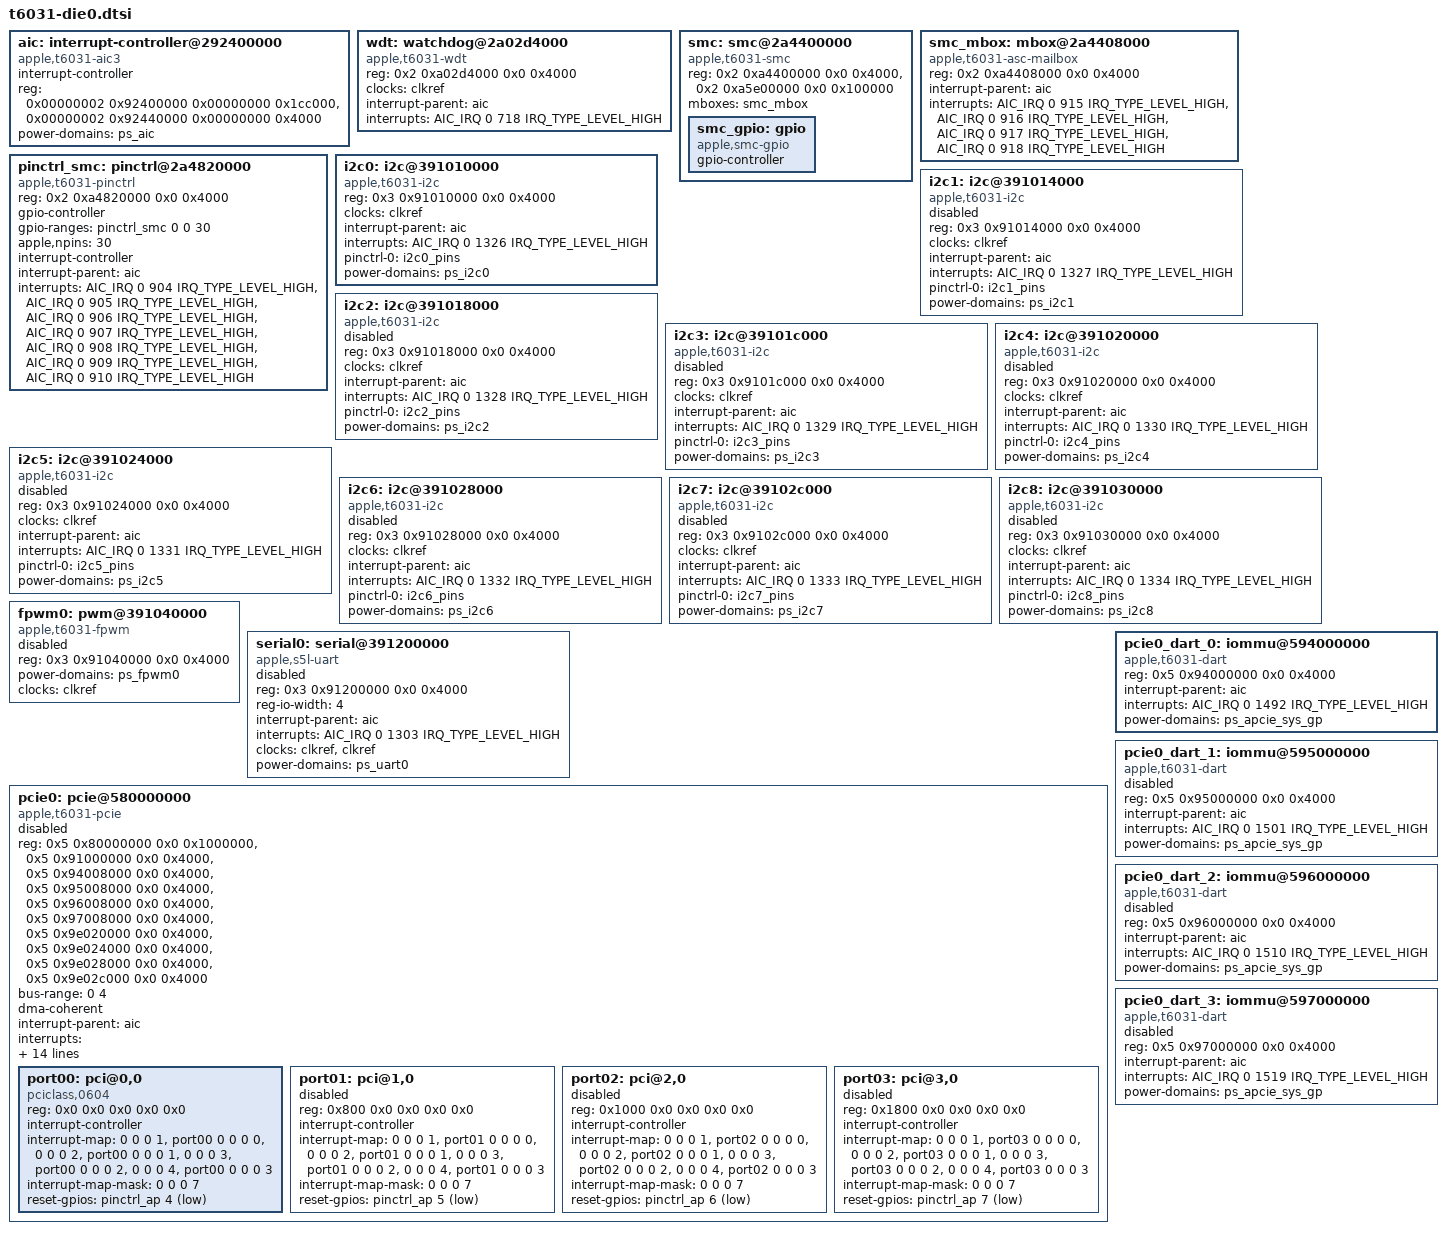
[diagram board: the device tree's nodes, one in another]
// SPDX-License-Identifier: GPL-2.0+ OR MIT
/*
 * Devices used on die 0 on the Apple T6032 "M3 Ultra" SoC and present on
 * Apple T6030 ("M3 Pro") and T6031 / T6034 ("M3 Max").
 *
 * Copyright The Asahi Linux Contributors
 */

#include <dt-bindings/gpio/gpio.h>

	aic: interrupt-controller@292400000 {
		compatible = "apple,t6031-aic3", "apple,t8122-aic3";
		#interrupt-cells = <4>;
		interrupt-controller;

		reg = <0x00000002 0x92400000 0x00000000 0x1cc000>,
		      <0x00000002 0x92440000 0x00000000 0x4000>;
		reg-names = "core", "event";
		power-domains = <&ps_aic>;
	};

	wdt: watchdog@2a02d4000 {
		compatible = "apple,t6031-wdt", "apple,t8103-wdt";
		reg = <0x2 0xa02d4000 0x0 0x4000>;
		clocks = <&clkref>;
		interrupt-parent = <&aic>;
		interrupts = <AIC_IRQ 0 718 IRQ_TYPE_LEVEL_HIGH>;
	};

	smc: smc@2a4400000 {
		compatible = "apple,t6031-smc", "apple,smc";
		reg =
			<0x2 0xa4400000 0x0 0x4000>,
			<0x2 0xa5e00000 0x0 0x100000>;
		reg-names = "smc", "sram";
		mboxes = <&smc_mbox>;

		smc_gpio: gpio {
			compatible = "apple,smc-gpio";
			#gpio-cells = <2>;
			gpio-controller;
		};
	};

	smc_mbox: mbox@2a4408000 {
		compatible = "apple,t6031-asc-mailbox", "apple,asc-mailbox-v4";
		reg = <0x2 0xa4408000 0x0 0x4000>;
		interrupt-parent = <&aic>;
		interrupts =
			<AIC_IRQ 0 915 IRQ_TYPE_LEVEL_HIGH>,
			<AIC_IRQ 0 916 IRQ_TYPE_LEVEL_HIGH>,
			<AIC_IRQ 0 917 IRQ_TYPE_LEVEL_HIGH>,
			<AIC_IRQ 0 918 IRQ_TYPE_LEVEL_HIGH>;
		interrupt-names =
			"send-empty",
			"send-not-empty",
			"recv-empty",
			"recv-not-empty";
		#mbox-cells = <0>;
	};

	pinctrl_smc: pinctrl@2a4820000 {
		compatible = "apple,t6031-pinctrl", "apple,t8103-pinctrl";
		reg = <0x2 0xa4820000 0x0 0x4000>;

		gpio-controller;
		#gpio-cells = <2>;
		gpio-ranges = <&pinctrl_smc 0 0 30>;
		apple,npins = <30>;

		interrupt-controller;
		#interrupt-cells = <2>;
		interrupt-parent = <&aic>;
		interrupts = <AIC_IRQ 0 904 IRQ_TYPE_LEVEL_HIGH>,
				<AIC_IRQ 0 905 IRQ_TYPE_LEVEL_HIGH>,
				<AIC_IRQ 0 906 IRQ_TYPE_LEVEL_HIGH>,
				<AIC_IRQ 0 907 IRQ_TYPE_LEVEL_HIGH>,
				<AIC_IRQ 0 908 IRQ_TYPE_LEVEL_HIGH>,
				<AIC_IRQ 0 909 IRQ_TYPE_LEVEL_HIGH>,
				<AIC_IRQ 0 910 IRQ_TYPE_LEVEL_HIGH>;
	};

	i2c0: i2c@391010000 {
		compatible = "apple,t6031-i2c", "apple,t8103-i2c";
		reg = <0x3 0x91010000 0x0 0x4000>;
		clocks = <&clkref>;
		interrupt-parent = <&aic>;
		interrupts = <AIC_IRQ 0 1326 IRQ_TYPE_LEVEL_HIGH>;
		pinctrl-0 = <&i2c0_pins>;
		pinctrl-names = "default";
		power-domains = <&ps_i2c0>;
		#address-cells = <0x1>;
		#size-cells = <0x0>;
	};

	i2c1: i2c@391014000 {
		compatible = "apple,t6031-i2c", "apple,t8103-i2c";
		reg = <0x3 0x91014000 0x0 0x4000>;
		clocks = <&clkref>;
		interrupt-parent = <&aic>;
		interrupts = <AIC_IRQ 0 1327 IRQ_TYPE_LEVEL_HIGH>;
		pinctrl-0 = <&i2c1_pins>;
		pinctrl-names = "default";
		power-domains = <&ps_i2c1>;
		#address-cells = <0x1>;
		#size-cells = <0x0>;
		status = "disabled";
	};

	i2c2: i2c@391018000 {
		compatible = "apple,t6031-i2c", "apple,t8103-i2c";
		reg = <0x3 0x91018000 0x0 0x4000>;
		clocks = <&clkref>;
		interrupt-parent = <&aic>;
		interrupts = <AIC_IRQ 0 1328 IRQ_TYPE_LEVEL_HIGH>;
		pinctrl-0 = <&i2c2_pins>;
		pinctrl-names = "default";
		power-domains = <&ps_i2c2>;
		#address-cells = <0x1>;
		#size-cells = <0x0>;
		status = "disabled";
	};

	i2c3: i2c@39101c000 {
		compatible = "apple,t6031-i2c", "apple,t8103-i2c";
		reg = <0x3 0x9101c000 0x0 0x4000>;
		clocks = <&clkref>;
		interrupt-parent = <&aic>;
		interrupts = <AIC_IRQ 0 1329 IRQ_TYPE_LEVEL_HIGH>;
		pinctrl-0 = <&i2c3_pins>;
		pinctrl-names = "default";
		power-domains = <&ps_i2c3>;
		#address-cells = <0x1>;
		#size-cells = <0x0>;
		status = "disabled";
	};

	i2c4: i2c@391020000 {
		compatible = "apple,t6031-i2c", "apple,t8103-i2c";
		reg = <0x3 0x91020000 0x0 0x4000>;
		clocks = <&clkref>;
		interrupt-parent = <&aic>;
		interrupts = <AIC_IRQ 0 1330 IRQ_TYPE_LEVEL_HIGH>;
		pinctrl-0 = <&i2c4_pins>;
		pinctrl-names = "default";
		power-domains = <&ps_i2c4>;
		#address-cells = <0x1>;
		#size-cells = <0x0>;
		status = "disabled";
	};

	i2c5: i2c@391024000 {
		compatible = "apple,t6031-i2c", "apple,t8103-i2c";
		reg = <0x3 0x91024000 0x0 0x4000>;
		clocks = <&clkref>;
		interrupt-parent = <&aic>;
		interrupts = <AIC_IRQ 0 1331 IRQ_TYPE_LEVEL_HIGH>;
		pinctrl-0 = <&i2c5_pins>;
		pinctrl-names = "default";
		power-domains = <&ps_i2c5>;
		#address-cells = <0x1>;
		#size-cells = <0x0>;
		status = "disabled";
	};

	i2c6: i2c@391028000 {
		compatible = "apple,t6031-i2c", "apple,t8103-i2c";
		reg = <0x3 0x91028000 0x0 0x4000>;
		clocks = <&clkref>;
		interrupt-parent = <&aic>;
		interrupts = <AIC_IRQ 0 1332 IRQ_TYPE_LEVEL_HIGH>;
		pinctrl-0 = <&i2c6_pins>;
		pinctrl-names = "default";
		power-domains = <&ps_i2c6>;
		#address-cells = <0x1>;
		#size-cells = <0x0>;
		status = "disabled";
	};

	i2c7: i2c@39102c000 {
		compatible = "apple,t6031-i2c", "apple,t8103-i2c";
		reg = <0x3 0x9102c000 0x0 0x4000>;
		clocks = <&clkref>;
		interrupt-parent = <&aic>;
		interrupts = <AIC_IRQ 0 1333 IRQ_TYPE_LEVEL_HIGH>;
		pinctrl-0 = <&i2c7_pins>;
		pinctrl-names = "default";
		power-domains = <&ps_i2c7>;
		#address-cells = <0x1>;
		#size-cells = <0x0>;
		status = "disabled";
	};

	i2c8: i2c@391030000 {
		compatible = "apple,t6031-i2c", "apple,t8103-i2c";
		reg = <0x3 0x91030000 0x0 0x4000>;
		clocks = <&clkref>;
		interrupt-parent = <&aic>;
		interrupts = <AIC_IRQ 0 1334 IRQ_TYPE_LEVEL_HIGH>;
		pinctrl-0 = <&i2c8_pins>;
		pinctrl-names = "default";
		power-domains = <&ps_i2c8>;
		#address-cells = <0x1>;
		#size-cells = <0x0>;
		status = "disabled";
	};

	fpwm0: pwm@391040000 {
		compatible = "apple,t6031-fpwm", "apple,s5l-fpwm";
		reg = <0x3 0x91040000 0x0 0x4000>;
		power-domains = <&ps_fpwm0>;
		clocks = <&clkref>;
		#pwm-cells = <2>;
		status = "disabled";
	};

	serial0: serial@391200000 {
		compatible = "apple,s5l-uart";
		reg = <0x3 0x91200000 0x0 0x4000>;
		reg-io-width = <4>;
		interrupt-parent = <&aic>;
		interrupts = <AIC_IRQ 0 1303 IRQ_TYPE_LEVEL_HIGH>;
		/*
		 * TODO: figure out the clocking properly, there may
		 * be a third selectable clock.
		 */
		clocks = <&clkref>, <&clkref>;
		clock-names = "uart", "clk_uart_baud0";
		power-domains = <&ps_uart0>;
		status = "disabled";
	};

	pcie0: pcie@580000000 {
		device_type = "pci";
		compatible = "apple,t6031-pcie", "apple,t6020-pcie";
		reg =
			<0x5 0x80000000 0x0 0x1000000>,
			<0x5 0x91000000 0x0 0x4000>,
			<0x5 0x94008000 0x0 0x4000>,
			<0x5 0x95008000 0x0 0x4000>,
			<0x5 0x96008000 0x0 0x4000>,
			<0x5 0x97008000 0x0 0x4000>,
			<0x5 0x9e020000 0x0 0x4000>,
			<0x5 0x9e024000 0x0 0x4000>,
			<0x5 0x9e028000 0x0 0x4000>,
			<0x5 0x9e02c000 0x0 0x4000>;
		reg-names =
			"config",
			"rc",
			"port0",
			"port1",
			"port2",
			"port3",
			"phy0",
			"phy1",
			"phy2",
			"phy3";
		ranges =
			<0x43000000 0x5 0xa0000000 0x5 0xa0000000 0x0
			0x20000000>,
			<0x02000000 0x0 0xc0000000 0x5 0xc0000000 0x0
			0x40000000>;
		#address-cells = <3>;
		bus-range = <0 4>;
		dma-coherent;
		interrupt-parent = <&aic>;
		interrupts =
			<AIC_IRQ 0 1491 IRQ_TYPE_LEVEL_HIGH>,
			<AIC_IRQ 0 1500 IRQ_TYPE_LEVEL_HIGH>,
			<AIC_IRQ 0 1509 IRQ_TYPE_LEVEL_HIGH>,
			<AIC_IRQ 0 1518 IRQ_TYPE_LEVEL_HIGH>;
		iommu-map =
			<0x100 &pcie0_dart_0 1 1>,
			<0x200 &pcie0_dart_1 1 1>,
			<0x300 &pcie0_dart_2 1 1>,
			<0x400 &pcie0_dart_3 1 1>;
		iommu-map-mask = <0xff00>;
		msi-controller;
		msi-parent = <&pcie0>;
		msi-ranges = <&aic AIC_IRQ 0 1854 IRQ_TYPE_EDGE_RISING 32>;
		pinctrl-0 = <&pcie_pins>;
		pinctrl-names = "default";
		power-domains = <&ps_apcie_sys_gp>;
		#size-cells = <2>;

		status = "disabled";

		port00: pci@0,0 {
			device_type = "pci";
			compatible = "pciclass,0604";
			reg = <0x0 0x0 0x0 0x0 0x0>;
			ranges;
			#address-cells = <3>;
			#interrupt-cells = <1>;
			interrupt-controller;
			interrupt-map =
				<0 0 0 1 &port00 0 0 0 0>,
				<0 0 0 2 &port00 0 0 0 1>,
				<0 0 0 3 &port00 0 0 0 2>,
				<0 0 0 4 &port00 0 0 0 3>;
			interrupt-map-mask = <0 0 0 7>;
			reset-gpios = <&pinctrl_ap 4 GPIO_ACTIVE_LOW>;
			#size-cells = <2>;
		};

		port01: pci@1,0 {
			device_type = "pci";
			reg = <0x800 0x0 0x0 0x0 0x0>;
			ranges;
			#address-cells = <3>;
			#interrupt-cells = <1>;
			interrupt-controller;
			interrupt-map =
				<0 0 0 1 &port01 0 0 0 0>,
				<0 0 0 2 &port01 0 0 0 1>,
				<0 0 0 3 &port01 0 0 0 2>,
				<0 0 0 4 &port01 0 0 0 3>;
			interrupt-map-mask = <0 0 0 7>;
			reset-gpios = <&pinctrl_ap 5 GPIO_ACTIVE_LOW>;
			#size-cells = <2>;

			status = "disabled";
		};

		port02: pci@2,0 {
			device_type = "pci";
			reg = <0x1000 0x0 0x0 0x0 0x0>;
			ranges;
			#address-cells = <3>;
			#interrupt-cells = <1>;
			interrupt-controller;
			interrupt-map =
				<0 0 0 1 &port02 0 0 0 0>,
				<0 0 0 2 &port02 0 0 0 1>,
				<0 0 0 3 &port02 0 0 0 2>,
				<0 0 0 4 &port02 0 0 0 3>;
			interrupt-map-mask = <0 0 0 7>;
			reset-gpios = <&pinctrl_ap 6 GPIO_ACTIVE_LOW>;
			#size-cells = <2>;

			status = "disabled";
		};

		port03: pci@3,0 {
			device_type = "pci";
			reg = <0x1800 0x0 0x0 0x0 0x0>;
			ranges;
			#address-cells = <3>;
			#interrupt-cells = <1>;
			interrupt-controller;
			interrupt-map =
				<0 0 0 1 &port03 0 0 0 0>,
				<0 0 0 2 &port03 0 0 0 1>,
				<0 0 0 3 &port03 0 0 0 2>,
				<0 0 0 4 &port03 0 0 0 3>;
			interrupt-map-mask = <0 0 0 7>;
			reset-gpios = <&pinctrl_ap 7 GPIO_ACTIVE_LOW>;
			#size-cells = <2>;

			status = "disabled";
		};
	};

	pcie0_dart_0: iommu@594000000 {
		compatible = "apple,t6031-dart", "apple,t8110-dart";
		reg = <0x5 0x94000000 0x0 0x4000>;
		interrupt-parent = <&aic>;
		interrupts = <AIC_IRQ 0 1492 IRQ_TYPE_LEVEL_HIGH>;
		#iommu-cells = <1>;
		power-domains = <&ps_apcie_sys_gp>;
	};

	pcie0_dart_1: iommu@595000000 {
		compatible = "apple,t6031-dart", "apple,t8110-dart";
		reg = <0x5 0x95000000 0x0 0x4000>;
		interrupt-parent = <&aic>;
		interrupts = <AIC_IRQ 0 1501 IRQ_TYPE_LEVEL_HIGH>;
		#iommu-cells = <1>;
		power-domains = <&ps_apcie_sys_gp>;

		status = "disabled";
	};

	pcie0_dart_2: iommu@596000000 {
		compatible = "apple,t6031-dart", "apple,t8110-dart";
		reg = <0x5 0x96000000 0x0 0x4000>;
		interrupt-parent = <&aic>;
		interrupts = <AIC_IRQ 0 1510 IRQ_TYPE_LEVEL_HIGH>;
		#iommu-cells = <1>;
		power-domains = <&ps_apcie_sys_gp>;

		status = "disabled";
	};

	pcie0_dart_3: iommu@597000000 {
		compatible = "apple,t6031-dart", "apple,t8110-dart";
		reg = <0x5 0x97000000 0x0 0x4000>;
		interrupt-parent = <&aic>;
		interrupts = <AIC_IRQ 0 1519 IRQ_TYPE_LEVEL_HIGH>;
		#iommu-cells = <1>;
		power-domains = <&ps_apcie_sys_gp>;

		status = "disabled";
	};
